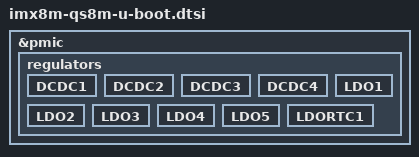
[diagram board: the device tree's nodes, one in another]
// SPDX-License-Identifier: (GPL-2.0 OR MIT)
/*
 * Copyright (C) 2023 Lothar Waßmann <LW@KARO-electronics.de>
 *
 */

&pmic {
	regulators {
		DCDC1 {
			bootph-pre-ram;
		};

		DCDC2 {
			bootph-pre-ram;
		};

		DCDC3 {
			bootph-pre-ram;
		};

		DCDC4 {
			bootph-pre-ram;
		};

		LDO1 {
			bootph-pre-ram;
		};

		LDO2 {
			bootph-pre-ram;
		};

		LDO3 {
			bootph-pre-ram;
		};

		LDO4 {
			bootph-pre-ram;
		};

		LDO5 {
			bootph-pre-ram;
		};

		LDORTC1 {
			bootph-pre-ram;
		};
	};
};
